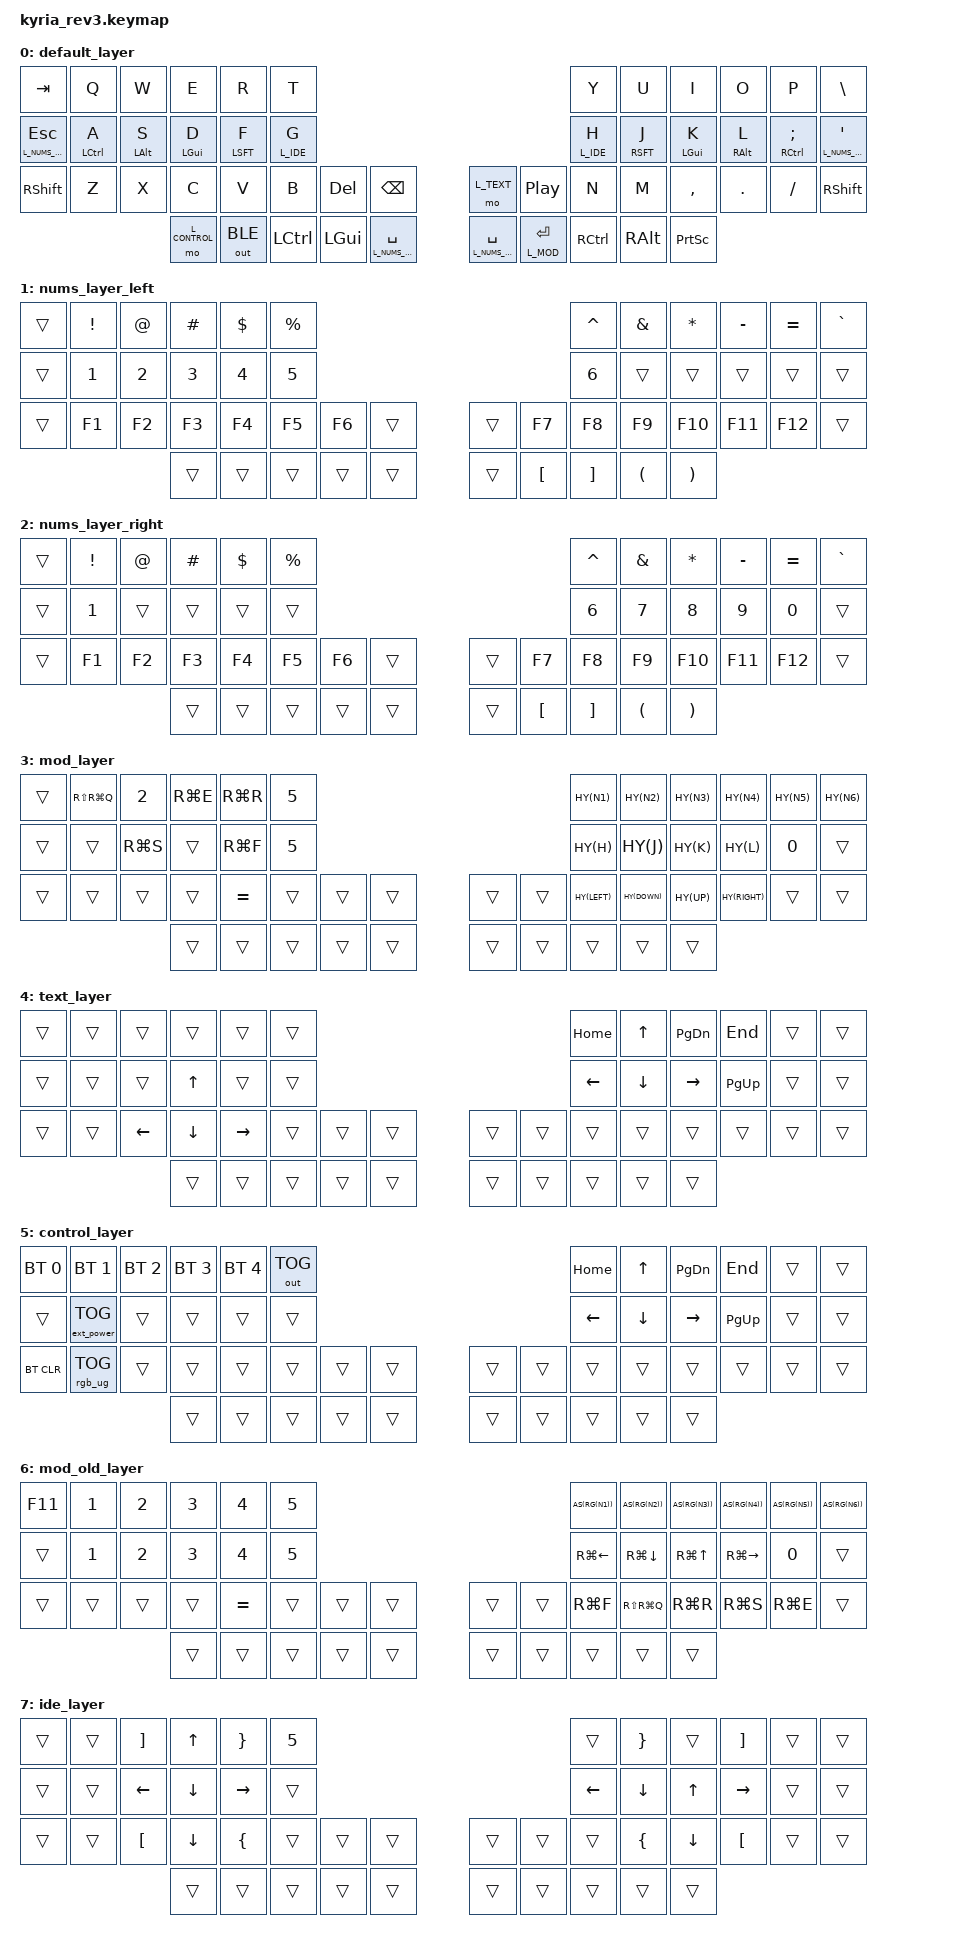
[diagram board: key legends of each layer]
#define DEFAULT 0
#define L_NUMS_LEFT 1
#define L_NUMS_RIGHT 2
#define L_MOD 3
#define L_TEXT 4
#define L_CONTROL 5
#define L_MOD_OLD 6
#define L_IDE 7

#include <behaviors.dtsi>
#include <dt-bindings/zmk/keys.h>
#include <dt-bindings/zmk/bt.h>
#include <dt-bindings/zmk/outputs.h>
#include <dt-bindings/zmk/ext_power.h>
#include <dt-bindings/zmk/rgb.h>

#define AS(keycode) &as LS(keycode) keycode     // Autoshift Macro
/ {
    behaviors {
        as: auto_shift {
            compatible = "zmk,behavior-hold-tap";
            label = "AUTO_SHIFT";
            #binding-cells = <2>;
            tapping_term_ms = <400>;
            quick_tap_ms = <0>;
            flavor = "tap-preferred";
            bindings = <&kp>, <&kp>;
        };
            hm: homerow_mods {
            compatible = "zmk,behavior-hold-tap";
            label = "HOMEROW_MODS";
            #binding-cells = <2>;
            require-prior-idle-ms = <120>;
            tapping-term-ms = <450>;
            quick_tap_ms = <300>;
            flavor = "balanced";
            bindings = <&kp>, <&kp>;
           };
            ltb: layer_tap_balanced {
            compatible = "zmk,behavior-hold-tap";
            label = "LAYER_TAP_BALANCED";
            #binding-cells = <2>;
            require-prior-idle-ms = <120>;
            tapping-term-ms = <450>;
            quick_tap_ms = <300>;
            flavor = "balanced";
            bindings = <&mo>, <&kp>;
           };
           };
macros {  
#define AS(keycode) &as LS(keycode) keycode     // Autoshift Macro
#define HY(keycode) &kp LS(LG(LA(LC(keycode))))
windowm: windowm {
            label = "windowm";
            compatible = "zmk,behavior-macro";
            #binding-cells = <0>;
bindings
    = <&macro_tap &kp RET>
    , <&macro_press &mo L_MOD &kp RGUI>
    , <&macro_pause_for_release>
    , <&macro_release &mo L_MOD &kp RGUI>
    ;
        };
    };
	keymap {
		compatible = "zmk,keymap";

		default_layer {
			bindings = <
	&kp TAB          &kp Q &kp W &kp E &kp R &kp T                                                   &kp Y &kp U  &kp I     &kp O   &kp P    &kp BSLH
	&lt L_NUMS_RIGHT ESC &hm LCTL  A  &hm LALT S  &hm LGUI D &hm LSFT F &lt L_IDE G                     &ltb L_IDE H  &hm RSFT J &hm LGUI K &hm RALT L  &hm RCTL SEMI &lt L_NUMS_LEFT SQT 
	&kp RSHFT       &kp Z &kp X &kp C &kp V &kp B   &kp DEL &kp BSPC						&mo L_TEXT     &kp  C_PLAY_PAUSE &kp N &kp M  &kp COMMA &kp DOT &kp FSLH &kp RSHFT
	                 &mo L_CONTROL &out OUT_BLE &kp LCTRL &kp LGUI &lt L_NUMS_RIGHT SPACE                 &lt L_NUMS_LEFT SPACE &lt L_MOD RET  &kp RCTRL &kp RALT &kp PSCRN
			>;
		};
		nums_layer_left {
			bindings = <
	 &trans &kp EXCL &kp AT &kp HASH &kp DLLR &kp PRCNT								&kp CARET &kp AMPS &kp STAR &kp MINUS &kp EQUAL &kp GRAVE
	 &trans &kp N1    &kp N2    &kp N3    &kp N4    &kp N5                                              &kp N6    &trans  &trans    &trans   &trans   &trans
	    &trans &kp F1 &kp F2    &kp F3    &kp F4    &kp F5    &kp F6 &trans                               &trans &kp F7    &kp F8    &kp F9  &kp F10   &kp F11 &kp F12 &trans
	                              &trans    &trans &trans  &trans    &trans                             &trans  &kp LBKT &kp RBKT   &kp LPAR    &kp RPAR     
			>;
		};

		nums_layer_right {
			bindings = <
	 &trans &kp EXCL &kp AT &kp HASH &kp DLLR &kp PRCNT								&kp CARET &kp AMPS &kp STAR &kp MINUS &kp EQUAL &kp GRAVE
	 &trans &kp N1    &trans   &trans   &trans   &trans                                             &kp N6    &kp N7    &kp N8    &kp N9    &kp N0    &trans
	    &trans &kp F1 &kp F2    &kp F3    &kp F4    &kp F5    &kp F6 &trans                               &trans &kp F7    &kp F8    &kp F9  &kp F10   &kp F11 &kp F12 &trans
	                              &trans    &trans &trans  &trans    &trans                             &trans  &kp LBKT &kp RBKT   &kp LPAR    &kp RPAR     
			>;
		};
	
		mod_layer {
			bindings = <
	&trans   &kp RS(RG(Q))    &kp N2    &kp RG(E)  &kp RG(R)    &kp N5                           HY(N1)   HY(N2)    HY(N3)   HY(N4)    HY(N5)   HY(N6)
	&trans   &trans &kp RG(S) &trans &kp RG(F)   &kp N5                                          HY(H)    HY(J)    HY(K)   HY(L)    &kp N0    &trans
	&trans    &trans    &trans    &trans    &kp EQUAL &trans    &trans    &trans      &trans    &trans    HY(LEFT)    HY(DOWN)    HY(UP)   HY(RIGHT) &trans  &trans  
	                              &trans    &trans   &trans    &trans    &trans      &trans    &trans    &trans    &trans    &trans    
			>;	
		};
		
		text_layer {
			bindings = <
	&trans    &trans    &trans    &trans    &trans    &trans                                              &kp HOME &kp UP  &kp PG_DN &kp END   &trans    &trans  
	&trans          &trans         &trans          &kp UP          &trans          &trans                                                    &kp LEFT  &kp DOWN  &kp RIGHT &kp PG_UP  &trans    &trans  
	&trans      &trans          &kp LEFT          &kp DOWN         &kp RIGHT          &trans          &trans    &trans      &trans    &trans    &trans    &trans    &trans    &trans    &trans    &trans  
	                                                &trans          &trans          &trans          &trans    &trans      &trans    &trans    &trans    &trans    &trans    
			>;
		};
		control_layer {
			bindings = <
	&bt BT_SEL 0    &bt BT_SEL 1    &bt BT_SEL 2    &bt BT_SEL 3    &bt BT_SEL 4    &out OUT_TOG                                              &kp HOME &kp UP  &kp PG_DN &kp END   &trans    &trans  
	&trans          &ext_power EP_TOG          &trans          &trans          &trans          &trans                                                    &kp LEFT  &kp DOWN  &kp RIGHT &kp PG_UP  &trans    &trans  
	&bt BT_CLR      &rgb_ug RGB_TOG          &trans          &trans          &trans          &trans          &trans    &trans      &trans    &trans    &trans    &trans    &trans    &trans    &trans    &trans  
	                                                &trans          &trans          &trans          &trans    &trans      &trans    &trans    &trans    &trans    &trans    
			>;
		};
		mod_old_layer {
			bindings = <
	&kp F11   &kp N1    &kp N2    &kp N3    &kp N4    &kp N5                                               AS(RG(N1))    AS(RG(N2))    AS(RG(N3))   AS(RG(N4))    AS(RG(N5))   AS(RG(N6))
	&trans   &kp N1    &kp N2    &kp N3    &kp N4    &kp N5                                              &kp RG(LEFT)    &kp RG(DOWN)    &kp RG(UP)   &kp RG(RIGHT)    &kp N0    &trans
	&trans    &trans    &trans    &trans    &kp EQUAL &trans    &trans    &trans      &trans    &trans    &kp RG(F)   &kp RS(RG(Q)) &kp RG(R)    &kp RG(S)    &kp RG(E)    &trans  
	                              &trans    &trans   &trans    &trans    &trans      &trans    &trans    &trans    &trans    &trans    
			>;	
			};
		ide_layer {
			bindings = <
	&trans   &trans   &kp RBKT  &kp UP  &kp RBRC      &kp N5                                      &trans  &kp RBRC   &trans   &kp RBKT    &trans   &trans
	&trans   &trans      &kp LEFT    &kp DOWN   &kp RIGHT  &trans                                    &kp LEFT  &kp DOWN  &kp UP   &kp RIGHT    &trans   &trans
	&trans    &trans    &kp LBKT   &kp DOWN  &kp LBRC    &trans    &trans      &trans    &trans  &trans &trans &kp LBRC     &kp DOWN  &kp LBKT &trans  &trans  
	                              &trans    &trans   &trans    &trans    &trans      &trans    &trans    &trans    &trans    &trans    
			>;	
		};
	};
};




